AUTOSAR XML (schema 00050)
package /ComponentTypes
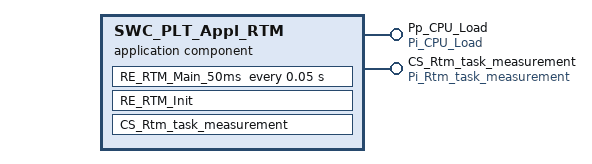
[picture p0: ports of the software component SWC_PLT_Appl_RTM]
  application sw component type SWC_PLT_Appl_RTM
    provide port Pp_CPU_Load: nonqueued-sender-com-spec{data-element=De_CPU_Load, init-value=fields=[CPU_Load:0, CPU_Load_Max:0, CPU_Load_Min:0, CPU_Load_Avg:0]}, provided-interface=Pi_CPU_Load
    provide port CS_Rtm_task_measurement: server-com-spec{operation=Operation, queue-length=1}, provided-interface=Pi_Rtm_task_measurement
    behavior SWC_PLT_Appl_RTM_InternalBehavior: handle-termination-and-restart=NO-SUPPORT
      init event SWC_PLT_Appl_RTM_InitEvent: start-on-event=RE_RTM_Init
      timing event TMT_RE_RTM_Main_50ms: start-on-event=RE_RTM_Main_50ms, period=0.05
      operation invoked event OIT_CS_Rtm_task_measurement_Operation_CS_Rtm_task_measurement_Operation: start-on-event=CS_Rtm_task_measurement, operation=CS_Rtm_task_measurement.Operation
      runnable RE_RTM_Init
        data-send-points:
          access SEND_Pp_CPU_Load_De_CPU_Load: accessed-variable=Pp_CPU_Load.De_CPU_Load
      runnable RE_RTM_Main_50ms
      runnable CS_Rtm_task_measurement
  swc implementation SWC_PLT_Appl_RTM_Implementation: behavior=SWC_PLT_Appl_RTM_InternalBehavior
    code-descriptors:
      code Default: artifact-descriptors=autosar-engineering-object=category=SWSRC
